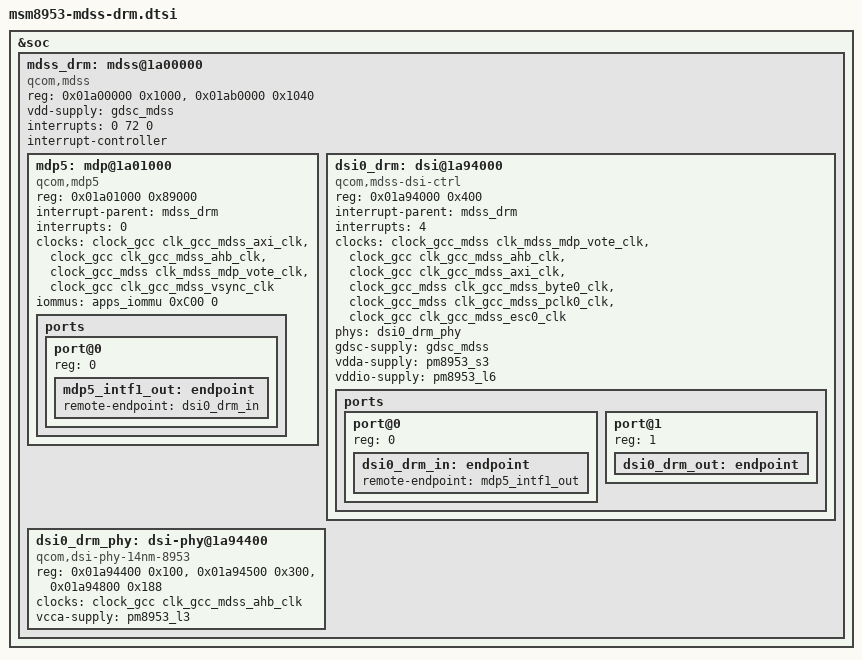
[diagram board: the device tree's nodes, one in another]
/* Copyright (c) 2024, Keyur Maru. All rights reserved.
 *
 * This program is free software; you can redistribute it and/or modify
 * it under the terms of the GNU General Public License version 2 and
 * only version 2 as published by the Free Software Foundation.
 *
 * This program is distributed in the hope that it will be useful,
 * but WITHOUT ANY WARRANTY; without even the implied warranty of
 * MERCHANTABILITY or FITNESS FOR A PARTICULAR PURPOSE.  See the
 * GNU General Public License for more details.
 */

/*
 * drm/msm MDP5 KMS display binding for msm8953/SDM632.
 *
 * This is the top-level "qcom,mdss" device that the drm/msm platform driver
 * (drivers/gpu/drm/msm/msm_drv.c dt_match: qcom,mdss -> MDP5) binds to. It
 * acts as the component master and wraps the MDP5, DSI controller and 14nm
 * DSI PHY as component-matched children (see add_display_components() and
 * add_components_mdp() in msm_drv.c).
 *
 * It coexists with the legacy fbdev/SDE MDSS binding in msm8953-mdss.dtsi:
 * that path is compiled out (CONFIG_FB_MSM not set) so its qcom,mdss_mdp /
 * qcom,mdss-dsi-ctrl nodes are present in DT but never bound. Only this node
 * is populated at runtime.
 *
 * Structural reference: mainline arch/arm64/boot/dts/qcom/msm8953.dtsi mdss
 * block (node shape, reg splits, port graph). Clock/regulator resources are
 * remapped to this tree's downstream providers (clock_gcc / clock_gcc_mdss /
 * gdsc_mdss / pm8953_*) and to the v4.11-era drm/msm clock-name convention
 * that our backported drivers expect (mdp5_kms.c: bus_clk/iface_clk/core_clk/
 * vsync_clk; dsi_host.c bus names mdp_core/iface/bus + byte_clk/pixel_clk/
 * core_clk; dsi_phy.c: iface_clk).
 */

&soc {
	mdss_drm: mdss@1a00000 {
		compatible = "qcom,mdss";
		reg = <0x01a00000 0x1000>,
		      <0x01ab0000 0x1040>;
		reg-names = "mdss_phys", "vbif_phys";

		vdd-supply = <&gdsc_mdss>;

		interrupts = <0 72 0>;
		interrupt-controller;
		#interrupt-cells = <1>;

		#address-cells = <1>;
		#size-cells = <1>;
		ranges;

		mdp5: mdp@1a01000 {
			compatible = "qcom,mdp5";
			reg = <0x01a01000 0x89000>;
			reg-names = "mdp_phys";

			interrupt-parent = <&mdss_drm>;
			interrupts = <0>;

			clocks = <&clock_gcc clk_gcc_mdss_axi_clk>,
				 <&clock_gcc clk_gcc_mdss_ahb_clk>,
				 <&clock_gcc_mdss clk_mdss_mdp_vote_clk>,
				 <&clock_gcc clk_gcc_mdss_vsync_clk>;
			clock-names = "bus_clk", "iface_clk",
				      "core_clk", "vsync_clk";

			iommus = <&apps_iommu 0xC00 0>;

			ports {
				#address-cells = <1>;
				#size-cells = <0>;

				port@0 {
					reg = <0>;
					mdp5_intf1_out: endpoint {
						remote-endpoint = <&dsi0_drm_in>;
					};
				};
			};
		};

		dsi0_drm: dsi@1a94000 {
			compatible = "qcom,mdss-dsi-ctrl";
			reg = <0x01a94000 0x400>;
			reg-names = "dsi_ctrl";

			interrupt-parent = <&mdss_drm>;
			interrupts = <4>;

			clocks = <&clock_gcc_mdss clk_mdss_mdp_vote_clk>,
				 <&clock_gcc clk_gcc_mdss_ahb_clk>,
				 <&clock_gcc clk_gcc_mdss_axi_clk>,
				 <&clock_gcc_mdss clk_gcc_mdss_byte0_clk>,
				 <&clock_gcc_mdss clk_gcc_mdss_pclk0_clk>,
				 <&clock_gcc clk_gcc_mdss_esc0_clk>;
			clock-names = "mdp_core", "iface", "bus",
				      "byte_clk", "pixel_clk", "core_clk";

			phys = <&dsi0_drm_phy>;

			gdsc-supply = <&gdsc_mdss>;
			vdda-supply = <&pm8953_s3>;
			vddio-supply = <&pm8953_l6>;

			#address-cells = <1>;
			#size-cells = <0>;

			ports {
				#address-cells = <1>;
				#size-cells = <0>;

				port@0 {
					reg = <0>;
					dsi0_drm_in: endpoint {
						remote-endpoint = <&mdp5_intf1_out>;
					};
				};

				port@1 {
					reg = <1>;
					dsi0_drm_out: endpoint {
					};
				};
			};
		};

		dsi0_drm_phy: dsi-phy@1a94400 {
			compatible = "qcom,dsi-phy-14nm-8953";
			reg = <0x01a94400 0x100>,
			      <0x01a94500 0x300>,
			      <0x01a94800 0x188>;
			reg-names = "dsi_phy", "dsi_phy_lane", "dsi_pll";

			#clock-cells = <1>;
			#phy-cells = <0>;

			clocks = <&clock_gcc clk_gcc_mdss_ahb_clk>;
			clock-names = "iface_clk";

			vcca-supply = <&pm8953_l3>;
		};
	};
};
